AUTOSAR XML (schema 00049)
package /Application/DltConfig
  dlt log channel to process mapping DltLogChannelToProcessMapping_BatteryMonitor_TO_BatteryMonitor: dlt-log-channel=BatteryMonitor, process=BatteryMonitor
  dlt log channel to process mapping DltLogChannelToProcessMapping_BmsInfo_TO_BmsInfo: dlt-log-channel=BmsInfo, process=BmsInfo
package /Application/Executable
  executable BatteryMonitor: category=APPLICATION_LEVEL, logging-behavior=USES-LOGGING, reporting-behavior=REPORTS-EXECUTION-STATE, version=1.0.0
    root sw component prototype AA: application-type=BatteryMonitor
  executable BmsInfo: category=APPLICATION_LEVEL, logging-behavior=USES-LOGGING, reporting-behavior=REPORTS-EXECUTION-STATE, version=1.0.0
    root sw component prototype AA: application-type=BmsInfo
package /Application/Manifest
  4 x service instance to port prototype mapping:
    BatteryMonitor_AA_RPort_BmsInfo: port-prototype=AA.RPort_BmsInfo, service-instance=EEVP_BatteryMonitor_Consumer_BmsInfo
    BatteryMonitor_AA_RPort_SOA_Mlm: port-prototype=AA.RPort_SOA_Mlm, service-instance=EEVP_BatteryMonitor_Consumer_SoaMlm
    BatteryMonitor_AA_RPort_SubscriptionManagement: port-prototype=AA.RPort_SubscriptionManagement, service-instance=EEVP_BatteryMonitor_Consumer_SubscriptionManagement
    BmsInfo_AA_PPort_BmsInfo: port-prototype=AA.PPort_BmsInfo, service-instance=Provider_BmsInfo
package /Application/Package/BatteryMonitor/SoftwareCluster_1_0_0
  software cluster BatteryMonitor_SoftwareCluster: category=APPLICATION_LAYER, contained-ar-element=BatteryMonitor, contained-process=BatteryMonitor, vendor-id=402, vendor-signature=ParaCertificate, version=1.0.0
package /Application/Package/BatteryMonitor/SoftwareCluster_1_0_1
  software cluster BatteryMonitor_SoftwareCluster: category=APPLICATION_LAYER, contained-ar-element=BatteryMonitor, contained-process=BatteryMonitor, vendor-id=402, vendor-signature=ParaCertificate, version=1.0.1
package /Application/Package/BatteryMonitor/SoftwareCluster_1_0_2
  software cluster BatteryMonitor_SoftwareCluster: category=APPLICATION_LAYER, contained-ar-element=BatteryMonitor, contained-process=BatteryMonitor, vendor-id=402, vendor-signature=ParaCertificate, version=1.0.2
package /Application/Package/BatteryMonitor/SoftwarePackage
  software package BatteryMonitor_InstallSoftwarePackage_1_0_0: action-type=INSTALL, compressed-software-package-size=0, maximum-supported-ucm-version=1.0.0, minimum-supported-ucm-version=1.0.0, packager-id=402, packager-signature=ParaCertificate, post-verification-reboot=false, pre-activate=SFG04.Off, pre-activation-reboot=false, software-cluster=SoftwareCluster_1_0_0/BatteryMonitor_SoftwareCluster, uncompressed-software-cluster-size=0, verify=SFG04.Verify
  software package BatteryMonitor_RemoveSoftwarePackage_1_0_2: action-type=REMOVE, compressed-software-package-size=0, maximum-supported-ucm-version=1.0.0, minimum-supported-ucm-version=1.0.0, packager-id=402, packager-signature=ParaCertificate, post-verification-reboot=false, pre-activate=SFG04.Off, pre-activation-reboot=false, software-cluster=SoftwareCluster_1_0_2/BatteryMonitor_SoftwareCluster, uncompressed-software-cluster-size=0, verify=SFG04.Verify
  software package BatteryMonitor_UpdateSoftwarePackage_1_0_1: action-type=UPDATE, compressed-software-package-size=0, maximum-supported-ucm-version=1.0.0, minimum-supported-ucm-version=1.0.0, packager-id=402, packager-signature=ParaCertificate, post-verification-reboot=false, pre-activate=SFG04.Off, pre-activation-reboot=false, software-cluster=SoftwareCluster_1_0_1/BatteryMonitor_SoftwareCluster, uncompressed-software-cluster-size=0, verify=SFG04.Verify
package /Application/Package/BatteryMonitor/VehiclePackage
  vehicle package BatteryMonitor_InstallVehiclePackage_1_0_0: vehicle-driver-notification{approval-required=true, notification-state=PROCESS}, packager-signature=ParaCertificate
    rollout-qualifications:
      vehicle rollout step RolloutQualification
        ucm-processings:
          ucm step UcmProcessing: ucm=BatteryMonitor_InstallVehiclePackage_1_0_0/EEVP_UCM
            software package step SoftwarePackageStep: process=BatteryMonitor_InstallSoftwarePackage_1_0_0, transfers=software-package-storing={storing=UCM, transfer=BatteryMonitor_InstallSoftwarePackage_1_0_0}
    ucm description EEVP_UCM: identifier=EEVP_UCM
  vehicle package BatteryMonitor_RemoveVehiclePackage_1_0_2: vehicle-driver-notification{approval-required=true, notification-state=PROCESS}, packager-signature=ParaCertificate
    rollout-qualifications:
      vehicle rollout step RolloutQualification
        ucm-processings:
          ucm step UcmProcessing: ucm=BatteryMonitor_RemoveVehiclePackage_1_0_2/EEVP_UCM
            software package step SoftwarePackageStep: process=BatteryMonitor_RemoveSoftwarePackage_1_0_2, transfers=software-package-storing={storing=UCM, transfer=BatteryMonitor_RemoveSoftwarePackage_1_0_2}
    ucm description EEVP_UCM: identifier=EEVP_UCM
  vehicle package BatteryMonitor_UpdateVehiclePackage_1_0_1: vehicle-driver-notification{approval-required=true, notification-state=PROCESS}, packager-signature=ParaCertificate
    rollout-qualifications:
      vehicle rollout step RolloutQualification
        ucm-processings:
          ucm step UcmProcessing: ucm=BatteryMonitor_UpdateVehiclePackage_1_0_1/EEVP_UCM
            software package step SoftwarePackageStep: process=BatteryMonitor_UpdateSoftwarePackage_1_0_1, transfers=software-package-storing={storing=UCM, transfer=BatteryMonitor_UpdateSoftwarePackage_1_0_1}
    ucm description EEVP_UCM: identifier=EEVP_UCM
package /Application/Process
  process BatteryMonitor: executable=BatteryMonitor, state-dependent-startup-config{function-group-state=[SFG04.On, SFG04.Verify], resource-group=DefaultResourceGroup, startup-config=DefaultStartupConfig}
    process state machine BatteryMonitor: type=ProcessState
  process BmsInfo: executable=BmsInfo, state-dependent-startup-config{function-group-state=[SFG04.On, SFG04.Verify], resource-group=DefaultResourceGroup, startup-config=DefaultStartupConfig}
    process state machine BmsInfo: type=ProcessState
package /Application/SwComponent
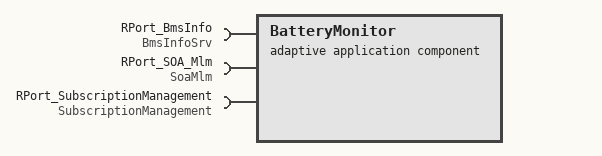
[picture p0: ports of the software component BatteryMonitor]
  adaptive application sw component type BatteryMonitor
    require port RPort_BmsInfo: required-interface=BmsInfoSrv
    require port RPort_SOA_Mlm: required-interface=SoaMlm
    require port RPort_SubscriptionManagement: required-interface=SubscriptionManagement
  adaptive application sw component type BmsInfo
    provide port PPort_BmsInfo: provided-interface=BmsInfoSrv
